# MIMXRT1051 register map
Vendor: nxp.com; File version: 1.0
CPU: CM7 r0p1, little endian, MPU, FPU, VTOR, 4 interrupt priority bits
Registers are 32-bit, read-write, reset 0x0 unless marked. A register's access mark holds for its fields unless they carry their own. Offsets are from the block's base; [hi:lo] are bit positions; 'fields as' and 'values as' point back to an identical list.

## USB_ANALOG
Base 0x400D8000; register names take the prefix USB_ANALOG_; alternate view of CCM_ANALOG
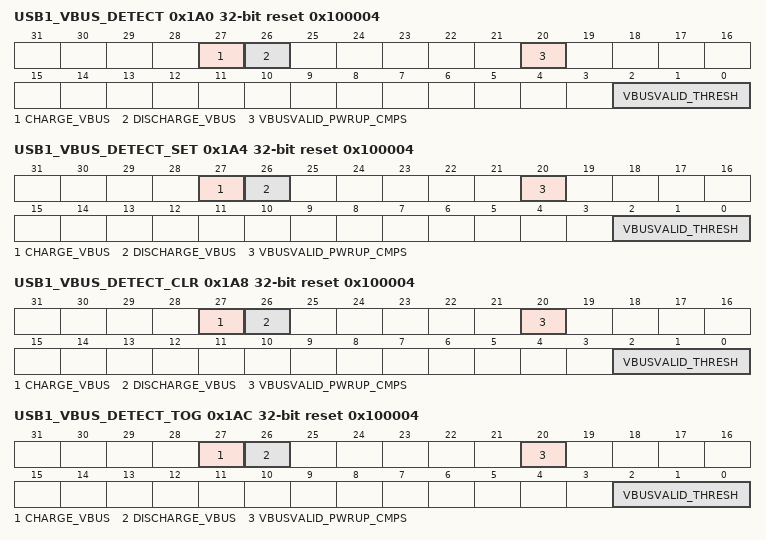
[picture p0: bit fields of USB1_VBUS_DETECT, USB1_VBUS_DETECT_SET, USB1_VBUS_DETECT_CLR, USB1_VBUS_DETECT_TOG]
0x1A0 USB1_VBUS_DETECT reset 0x100004 — USB VBUS Detect Register
  [27] CHARGE_VBUS — USB OTG charge VBUS.
  [26] DISCHARGE_VBUS — USB OTG discharge VBUS.
  [20] VBUSVALID_PWRUP_CMPS — Powers up comparators for vbus_valid detector.
  [2:0] VBUSVALID_THRESH — Set the threshold for the VBUSVALID comparator
    0=4V0 (4.0V); 1=4V1 (4.1V); 2=4V2 (4.2V); 3=4V3 (4.3V); 4=4V4 (4.4V (default)); 5=4V5 (4.5V); 6=4V6 (4.6V); 7=4V7 (4.7V)
0x1A4 USB1_VBUS_DETECT_SET reset 0x100004 — USB VBUS Detect Register
  fields as USB1_VBUS_DETECT
0x1A8 USB1_VBUS_DETECT_CLR reset 0x100004 — USB VBUS Detect Register
  fields as USB1_VBUS_DETECT
0x1AC USB1_VBUS_DETECT_TOG reset 0x100004 — USB VBUS Detect Register
  fields as USB1_VBUS_DETECT
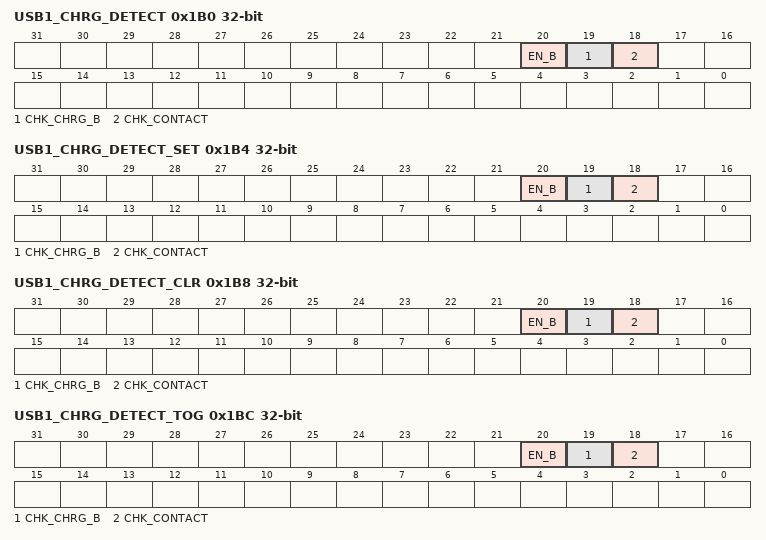
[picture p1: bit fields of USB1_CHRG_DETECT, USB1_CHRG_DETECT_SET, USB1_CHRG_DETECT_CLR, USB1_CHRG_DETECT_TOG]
0x1B0 USB1_CHRG_DETECT — USB Charger Detect Register
  [20] EN_B — Control the charger detector.
    0=ENABLE (Enable the charger detector.); 1=DISABLE (Disable the charger detector.)
  [19] CHK_CHRG_B — Check the charger connection
    0=CHECK (Check whether a charger (either a dedicated charger or a host charger) is connected to USB port.); 1=NO_CHECK (Do not check whether a charger is connected to the USB port.)
  [18] CHK_CONTACT — Check the contact of USB plug
    0=NO_CHECK (Do not check the contact of USB plug.); 1=CHECK (Check whether the USB plug has been in contact with each other)
0x1B4 USB1_CHRG_DETECT_SET — USB Charger Detect Register
  fields as USB1_CHRG_DETECT
0x1B8 USB1_CHRG_DETECT_CLR — USB Charger Detect Register
  fields as USB1_CHRG_DETECT
0x1BC USB1_CHRG_DETECT_TOG — USB Charger Detect Register
  fields as USB1_CHRG_DETECT
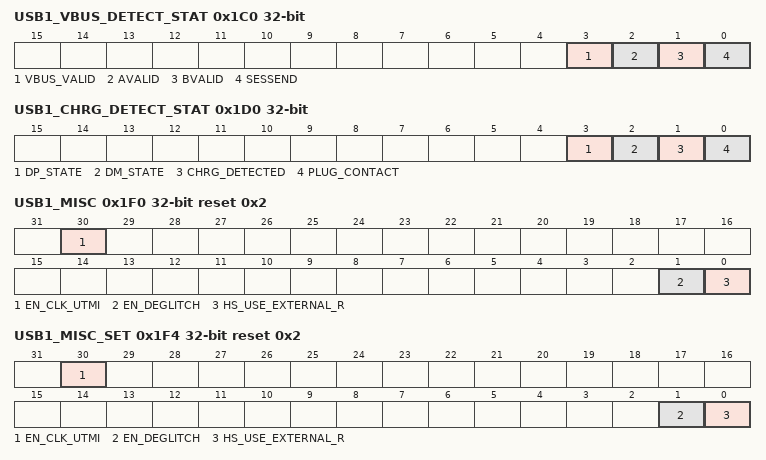
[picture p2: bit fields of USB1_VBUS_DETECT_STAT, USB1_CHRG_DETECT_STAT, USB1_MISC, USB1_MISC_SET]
0x1C0 USB1_VBUS_DETECT_STAT ro — USB VBUS Detect Status Register
  [3] VBUS_VALID — VBus valid for USB OTG
  [2] AVALID — Indicates VBus is valid for a A-peripheral
  [1] BVALID — Indicates VBus is valid for a B-peripheral
  [0] SESSEND — Session End for USB OTG
0x1D0 USB1_CHRG_DETECT_STAT ro — USB Charger Detect Status Register
  [3] DP_STATE — DP line state output of the charger detector.
  [2] DM_STATE — DM line state output of the charger detector.
  [1] CHRG_DETECTED — State of charger detection. This bit is a read only version of the state of the analog signal.
    0=CHARGER_NOT_PRESENT (The USB port is not connected to a charger.); 1=CHARGER_PRESENT (A charger (either a dedicated charger or a host charger) is connected to the USB port.)
  [0] PLUG_CONTACT — State of the USB plug contact detector.
    0=NO_CONTACT (The USB plug has not made contact.); 1=GOOD_CONTACT (The USB plug has made good contact.)
0x1E0 USB1_LOOPBACK — USB Loopback Test Register
  [0] UTMI_TESTSTART — Setting this bit can enable 1
0x1E4 USB1_LOOPBACK_SET — USB Loopback Test Register
  [0] UTMI_TESTSTART — Setting this bit can enable 1
0x1E8 USB1_LOOPBACK_CLR — USB Loopback Test Register
  [0] UTMI_TESTSTART — Setting this bit can enable 1
0x1EC USB1_LOOPBACK_TOG — USB Loopback Test Register
  [0] UTMI_TESTSTART — Setting this bit can enable 1
0x1F0 USB1_MISC reset 0x2 — USB Misc Register
  [30] EN_CLK_UTMI — Enables the clk to the UTMI block.
  [1] EN_DEGLITCH — Enable the deglitching circuit of the USB PLL output.
  [0] HS_USE_EXTERNAL_R — Use external resistor to generate the current bias for the high speed transmitter
0x1F4 USB1_MISC_SET reset 0x2 — USB Misc Register
  fields as USB1_MISC
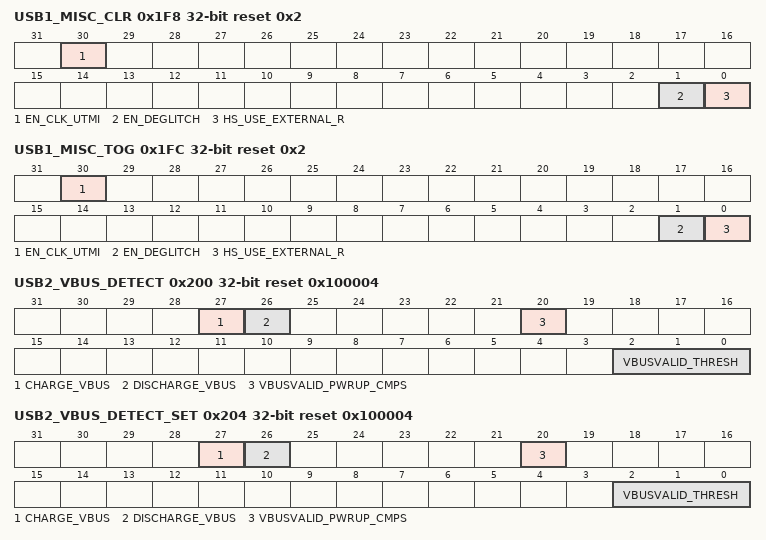
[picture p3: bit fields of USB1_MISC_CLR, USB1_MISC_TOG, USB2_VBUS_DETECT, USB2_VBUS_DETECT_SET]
0x1F8 USB1_MISC_CLR reset 0x2 — USB Misc Register
  fields as USB1_MISC
0x1FC USB1_MISC_TOG reset 0x2 — USB Misc Register
  fields as USB1_MISC
0x200 USB2_VBUS_DETECT reset 0x100004 — USB VBUS Detect Register
  fields as USB1_VBUS_DETECT
0x204 USB2_VBUS_DETECT_SET reset 0x100004 — USB VBUS Detect Register
  fields as USB1_VBUS_DETECT
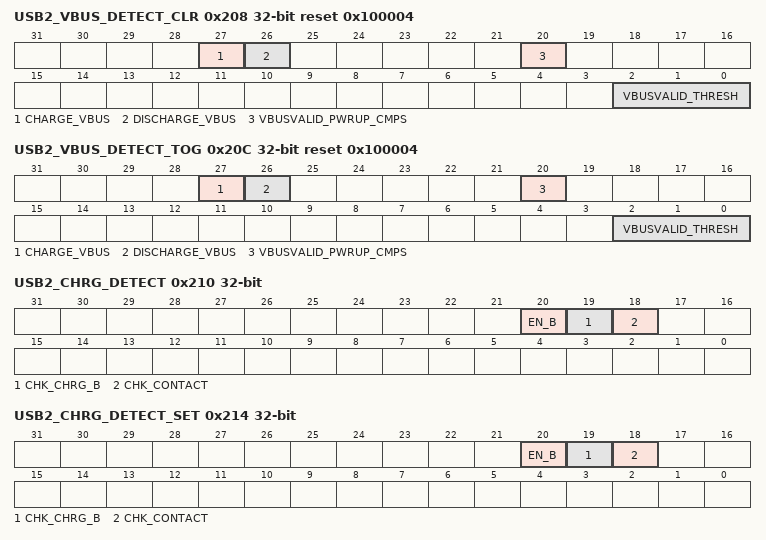
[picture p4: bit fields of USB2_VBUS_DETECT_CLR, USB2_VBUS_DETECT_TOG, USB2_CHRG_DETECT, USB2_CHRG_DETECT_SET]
0x208 USB2_VBUS_DETECT_CLR reset 0x100004 — USB VBUS Detect Register
  fields as USB1_VBUS_DETECT
0x20C USB2_VBUS_DETECT_TOG reset 0x100004 — USB VBUS Detect Register
  fields as USB1_VBUS_DETECT
0x210 USB2_CHRG_DETECT — USB Charger Detect Register
  fields as USB1_CHRG_DETECT
0x214 USB2_CHRG_DETECT_SET — USB Charger Detect Register
  fields as USB1_CHRG_DETECT
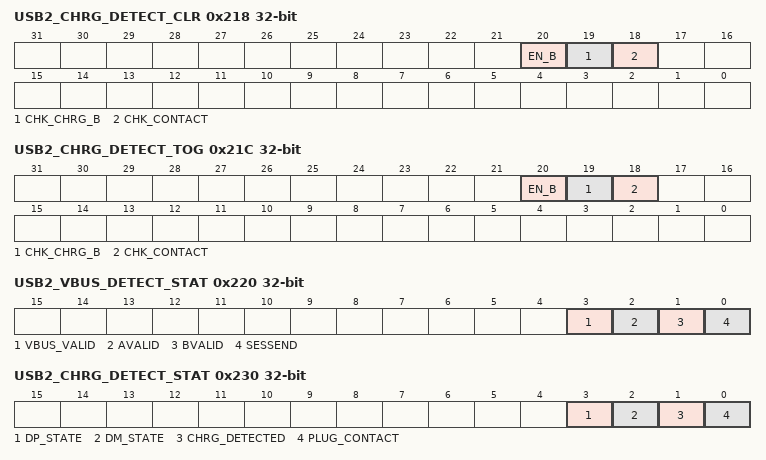
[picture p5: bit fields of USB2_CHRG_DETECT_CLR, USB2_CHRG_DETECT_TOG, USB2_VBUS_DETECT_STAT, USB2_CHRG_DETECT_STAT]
0x218 USB2_CHRG_DETECT_CLR — USB Charger Detect Register
  fields as USB1_CHRG_DETECT
0x21C USB2_CHRG_DETECT_TOG — USB Charger Detect Register
  fields as USB1_CHRG_DETECT
0x220 USB2_VBUS_DETECT_STAT ro — USB VBUS Detect Status Register
  fields as USB1_VBUS_DETECT_STAT
0x230 USB2_CHRG_DETECT_STAT ro — USB Charger Detect Status Register
  fields as USB1_CHRG_DETECT_STAT
0x240 USB2_LOOPBACK — USB Loopback Test Register
  [0] UTMI_TESTSTART — Setting this bit can enable 1
0x244 USB2_LOOPBACK_SET — USB Loopback Test Register
  [0] UTMI_TESTSTART — Setting this bit can enable 1
0x248 USB2_LOOPBACK_CLR — USB Loopback Test Register
  [0] UTMI_TESTSTART — Setting this bit can enable 1
0x24C USB2_LOOPBACK_TOG — USB Loopback Test Register
  [0] UTMI_TESTSTART — Setting this bit can enable 1
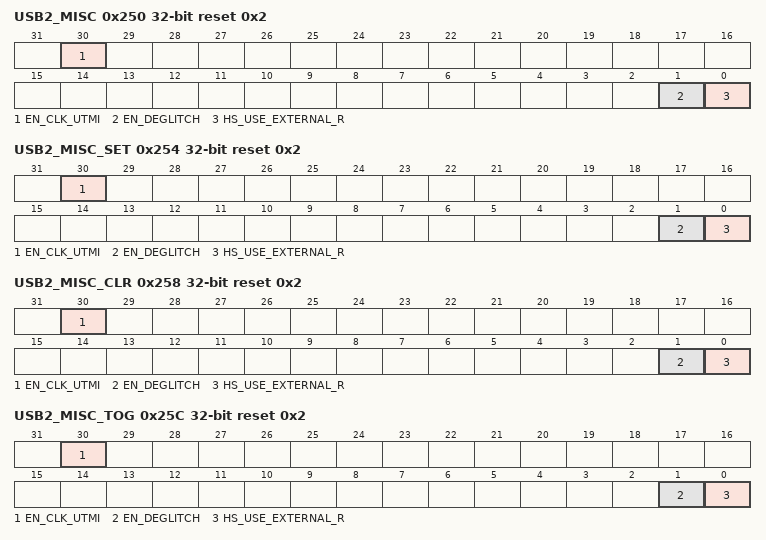
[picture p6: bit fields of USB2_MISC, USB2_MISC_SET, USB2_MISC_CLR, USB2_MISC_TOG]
0x250 USB2_MISC reset 0x2 — USB Misc Register
  fields as USB1_MISC
0x254 USB2_MISC_SET reset 0x2 — USB Misc Register
  fields as USB1_MISC
0x258 USB2_MISC_CLR reset 0x2 — USB Misc Register
  fields as USB1_MISC
0x25C USB2_MISC_TOG reset 0x2 — USB Misc Register
  fields as USB1_MISC
0x260 DIGPROG ro reset 0x6A0001 — Chip Silicon Version
  [31:0] SILICON_REVISION — Chip silicon revision
    0x6A0001=Silicon revision 1.1

## Notices in the file
Copyright 2016-2021 NXP
All rights reserved.
SPDX-License-Identifier: BSD-3-Clause
